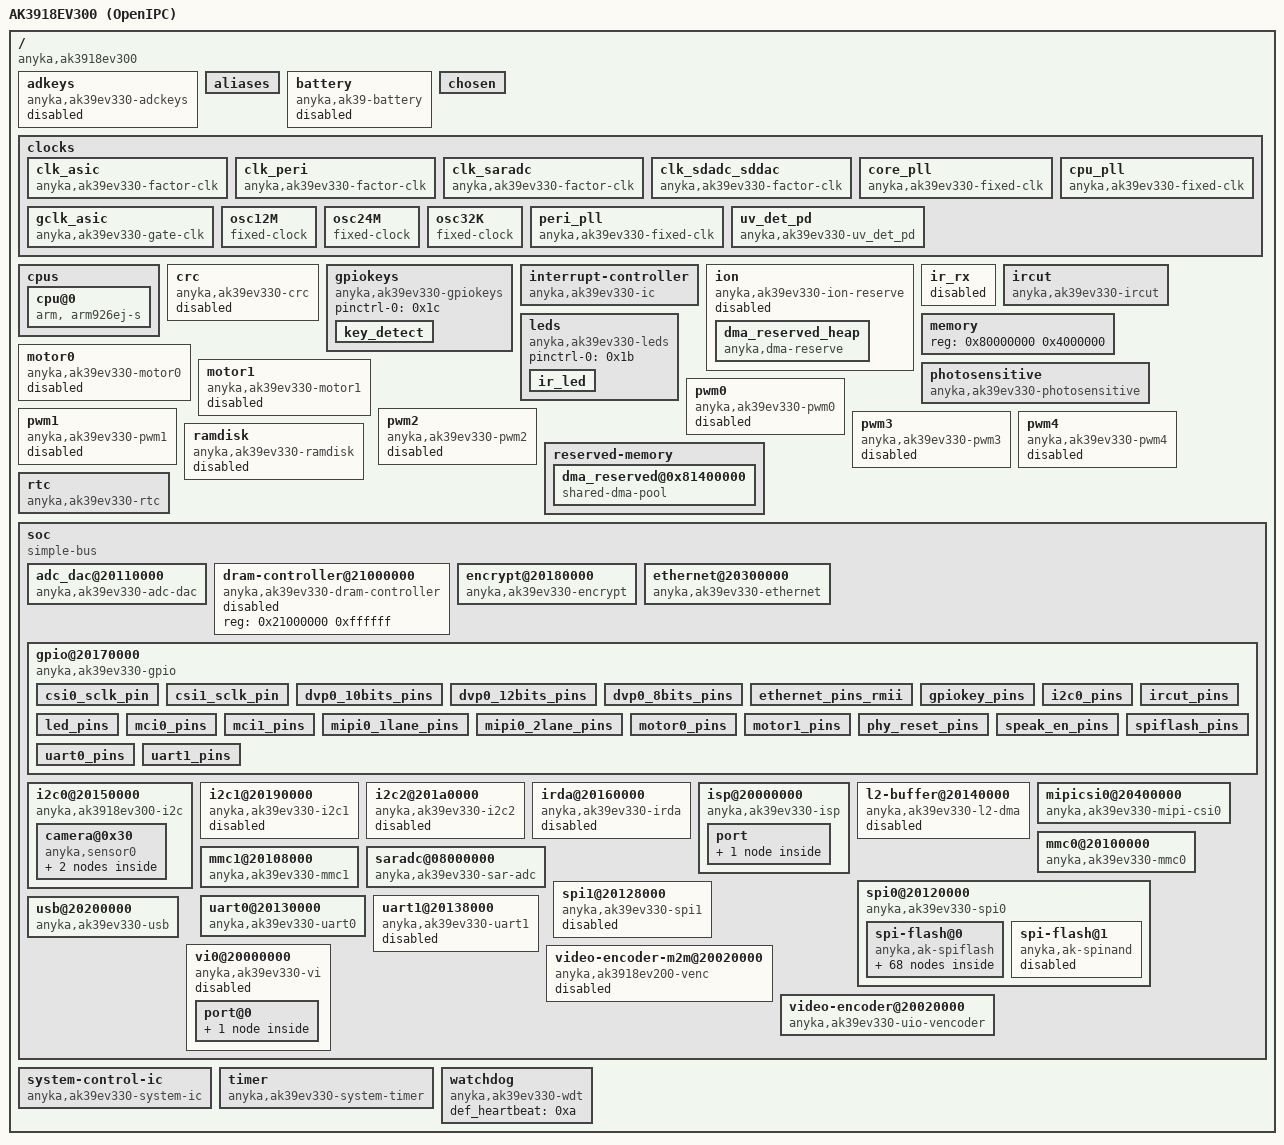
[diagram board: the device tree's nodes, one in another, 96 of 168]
/dts-v1/;

/ {
    #address-cells = <0x1>;
    #size-cells = <0x1>;
    compatible = "anyka,ak3918ev300";
    interrupt-parent = <0x1>;
    model = "AK3918EV300 (OpenIPC)";
    version = "V1.0.00";
    adkeys {
        compatible = "anyka,ak39ev330-adckeys";
        status = "disable";
    };
    aliases {
        adkeys = "/adkeys";
        ethernet0 = "/soc/ethernet@20300000";
        gpio = "/soc/gpio@20170000";
        gpiokeys = "/gpiokeys";
        i2c0 = "/soc/i2c0@20150000";
        i2c1 = "/soc/i2c1@20190000";
        i2c2 = "/soc/i2c2@201a0000";
        intc = "/interrupt-controller";
        ir_rx = "/ir_rx";
        leds = "/leds";
        mipicsi0 = "/soc/mipicsi0@20400000";
        mmc0 = "/soc/mmc0@20100000";
        mmc1 = "/soc/mmc1@20108000";
        motor0 = "/motor0";
        motor1 = "/motor1";
        pwm0 = "/pwm0";
        pwm1 = "/pwm1";
        pwm2 = "/pwm2";
        pwm3 = "/pwm3";
        pwm4 = "/pwm4";
        rtc = "/rtc";
        spi0 = "/soc/spi0@20120000";
        spi1 = "/soc/spi1@20128000";
        uart0 = "/soc/uart0@20130000";
        uart1 = "/soc/uart1@20138000";
        usb = "/soc/usb@20200000";
        watchdog = "/watchdog";
    };
    battery {
        compatible = "anyka,ak39-battery";
        status = "disable";
    };
    chosen {
        bootargs = "console=ttySAK0,115200n8 mem=64M root=/dev/ram0 rdinit=/init initrd=0x80900000,3491008 mtdparts=spi0.0:8192k(all)ro initcall_blacklist=gpio_keys_init panic=0 loglevel=7";
    };
    clocks {
        clk_asic {
            #clock-cells = <0x1>;
            clock-id = <0x0 0x1>;
            clock-output-names = "adchs", "dachs";
            clocks = <0x20>;
            compatible = "anyka,ak39ev330-factor-clk";
            linux,phandle = <0xb>;
            phandle = <0xb>;
        };
        clk_peri {
            #clock-cells = <0x1>;
            clock-id = <0x2 0x3 0x4 0x5 0x6>;
            clock-output-names = "csi_sclk", "csi_pclk", "dsi_pclk", "opclk", "usb_phy";
            clocks = <0x21>;
            compatible = "anyka,ak39ev330-factor-clk";
            linux,phandle = <0x14>;
            phandle = <0x14>;
        };
        clk_saradc {
            #clock-cells = <0x1>;
            clock-id = <0x9>;
            clock-output-names = "saradc";
            clocks = <0x22>;
            compatible = "anyka,ak39ev330-factor-clk";
            linux,phandle = <0xe>;
            phandle = <0xe>;
        };
        clk_sdadc_sddac {
            #clock-cells = <0x1>;
            clock-id = <0x7 0x8>;
            clock-output-names = "clk_sdadc", "clk_sddac";
            clocks = <0x20>;
            compatible = "anyka,ak39ev330-factor-clk";
            linux,phandle = <0xa>;
            phandle = <0xa>;
        };
        core_pll {
            #clock-cells = <0x0>;
            clock-div-n = <0x3>;
            clock-div-od = <0x0>;
            clock-frequency = <0x2625a000>;
            clock-id = <0x3>;
            clock-output-names = "core_pll";
            clocks = <0x1f>;
            compatible = "anyka,ak39ev330-fixed-clk";
            linux,phandle = <0x20>;
            phandle = <0x20>;
        };
        cpu_pll {
            #clock-cells = <0x1>;
            clock-id = <0x0 0x1 0x2>;
            clock-output-names = "jclk", "hclk", "dphy";
            clocks = <0x1f>;
            compatible = "anyka,ak39ev330-fixed-clk";
        };
        gclk_asic {
            #clock-cells = <0x1>;
            clock-ctrlbit = [00 00 00 01 00 00 00 02 00 00 00 03 00 00 00 04 00 00 00 05 00 00 00 06 00 00 00 07 00 00 00 08 00 00 00 09 00 00 00 0a 00 00 00 0b 00 00 00 0c 00 00 00 0d 00 00 00 0e 00 00 00 0f 00 00 00 10 00 00 00 11 00 00 00 13 00 00 00 14 00 00 00 1f 00 00 00 12];
            clock-output-names = "mmc0", "mmc1", "adc", "dac", "spi0", "spi1", "uart0", "uart1", "l2buffer", "i2c0", "irda", "gpio", "ethernet", "encrypt", "usb-otg", "mipi", "i2c1", "isp", "vencoder", "i2c2", "sensor-sclk";
            clocks = <0x20>;
            compatible = "anyka,ak39ev330-gate-clk";
            linux,phandle = <0x5>;
            phandle = <0x5>;
        };
        osc12M {
            #clock-cells = <0x0>;
            clock-frequency = <0xb71b00>;
            clock-output-names = "osc12M";
            clocks = <0x1f>;
            compatible = "fixed-clock";
            linux,phandle = <0x22>;
            phandle = <0x22>;
        };
        osc24M {
            #clock-cells = <0x0>;
            clock-frequency = <0x16e3600>;
            clock-output-names = "osc24M";
            compatible = "fixed-clock";
            linux,phandle = <0x1f>;
            phandle = <0x1f>;
        };
        osc32K {
            #clock-cells = <0x0>;
            clock-frequency = <0x8000>;
            clock-output-names = "osc32K";
            compatible = "fixed-clock";
        };
        peri_pll {
            #clock-cells = <0x0>;
            clock-div-n = <0x2>;
            clock-div-od = <0x1>;
            clock-frequency = <0x23c34600>;
            clock-id = <0x4>;
            clock-output-names = "peri_pll";
            clocks = <0x1f>;
            compatible = "anyka,ak39ev330-fixed-clk";
            linux,phandle = <0x21>;
            phandle = <0x21>;
        };
        uv_det_pd {
            compatible = "anyka,ak39ev330-uv_det_pd";
            enable = <0x1>;
            status = "okay";
            threshold = <0x2>;
        };
    };
    cpus {
        #address-cells = <0x1>;
        #size-cells = <0x0>;
        cpu@0 {
            bus-frequency = <0x0>;
            clock-frequency = <0x0>;
            compatible = "arm, arm926ej-s";
            d-cache-line-size = <0x20>;
            d-cache-size = <0x8000>;
            device_type = "cpu";
            i-cache-line-size = <0x20>;
            i-cache-size = <0x8000>;
            reg = <0x0>;
            timebase-frequency = <0x0>;
        };
    };
    crc {
        compatible = "anyka,ak39ev330-crc";
        status = "disable";
    };
    gpiokeys {
        #address-cells = <0x1>;
        #size-cells = <0x0>;
        compatible = "anyka,ak39ev330-gpiokeys";
        pinctrl-0 = <0x1c>;
        pinctrl-names = "default";
        status = "okay";
        key_detect {
            debounce-interval = <0x64>;
            gpios = <0xd 0x54 0x1>;
            label = "key_detect";
            linux,code = <0x74>;
            wakeup-source;
        };
    };
    interrupt-controller {
        #interrupt-cells = <0x2>;
        bank_irqs = <0x17 0x10>;
        compatible = "anyka,ak39ev330-ic";
        interrupt-controller;
        linux,phandle = <0x1>;
        phandle = <0x1>;
    };
    ion {
        #address-cells = <0x1>;
        #size-cells = <0x1>;
        compatible = "anyka,ak39ev330-ion-reserve";
        heaps-nr = <0x1>;
        memory-region = <0x6>;
        ranges;
        status = "disabled";
        dma_reserved_heap {
            align = <0x4>;
            base-address = <0x81400000>;
            compatible = "anyka,dma-reserve";
            ion-id = <0x1>;
            ion-type = <0x1>;
            size = <0x2000000>;
            status = "okay";
        };
    };
    ir_rx {
        status = "disable";
    };
    ircut {
        compatible = "anyka,ak39ev330-ircut";
        ircut-a = "0";
        ircut-a-day-level = "0";
        pinctrl-0 = <0x1a>;
        pinctrl-names = "default";
        status = "okay";
    };
    leds {
        compatible = "anyka,ak39ev330-leds";
        pinctrl-0 = <0x1b>;
        pinctrl-names = "default";
        status = "okay";
        ir_led {
            gpios = <0xd 0x5 0x0>;
            label = "irled";
        };
    };
    memory {
        device_type = "memory";
        reg = <0x80000000 0x4000000>;
    };
    motor0 {
        attach-timer = <0x2>;
        boundary-steps = <0x32>;
        compatible = "anyka,ak39ev330-motor0";
        part-number = "HZF-24BYJ48";
        pinctrl-0 = <0x1d>;
        pinctrl-names = "default";
        pwm-pins = <0x44 0x9 0x8 0x7>;
        pwm-tbl-cw = <0x9 0x1 0x3 0x2 0x6 0x4 0xc 0x8>;
        speed-step = <0xc8>;
        status = "disable";
        steps-one-circle = <0x1000>;
        total-steps = <0x9c4>;
    };
    motor1 {
        attach-timer = <0x3>;
        boundary-steps = <0x32>;
        compatible = "anyka,ak39ev330-motor1";
        part-number = "HZF-24BYJ48";
        pinctrl-0 = <0x1e>;
        pinctrl-names = "default";
        pwm-pins = <0x6 0x43 0x42 0x41>;
        pwm-tbl-cw = <0x9 0x1 0x3 0x2 0x6 0x4 0xc 0x8>;
        speed-step = <0xc8>;
        status = "disable";
        steps-one-circle = <0x1000>;
        total-steps = <0x258>;
    };
    photosensitive {
        compatible = "anyka,ak39ev330-photosensitive";
        photosensitive-day-level = "high";
        photosensitive-higher-level = "900";
        photosensitive-lower-level = "400";
        photosensitive-port = "saradc0";
        status = "okay";
    };
    pwm0 {
        compatible = "anyka,ak39ev330-pwm0";
        duty-ns = <0x7a120>;
        period-ns = <0xf4240>;
        pinctrl-names = "default";
        pwm-enable = <0x1>;
        status = "disable";
    };
    pwm1 {
        compatible = "anyka,ak39ev330-pwm1";
        duty-ns = <0x7a120>;
        period-ns = <0xf4240>;
        pinctrl-names = "default";
        pwm-enable = <0x1>;
        status = "disable";
    };
    pwm2 {
        compatible = "anyka,ak39ev330-pwm2";
        duty-ns = <0x7a120>;
        period-ns = <0xf4240>;
        pinctrl-names = "default";
        pwm-enable = <0x1>;
        status = "disable";
    };
    pwm3 {
        compatible = "anyka,ak39ev330-pwm3";
        duty-ns = <0x7a120>;
        period-ns = <0xf4240>;
        pinctrl-names = "default";
        pwm-enable = <0x1>;
        status = "disable";
    };
    pwm4 {
        compatible = "anyka,ak39ev330-pwm4";
        duty-ns = <0x7a120>;
        period-ns = <0xf4240>;
        pinctrl-names = "default";
        pwm-enable = <0x1>;
        status = "disable";
    };
    ramdisk {
        compatible = "anyka,ak39ev330-ramdisk";
        status = "disabled";
    };
    reserved-memory {
        #address-cells = <0x1>;
        #size-cells = <0x1>;
        ranges;
        dma_reserved@0x81400000 {
            compatible = "shared-dma-pool";
            linux,phandle = <0x6>;
            no-map;
            phandle = <0x6>;
            reg = <0x81400000 0x1800000>;
            size = <0x1800000>;
            status = "okay";
        };
    };
    rtc {
        adjust-time = <0x1d4c0>;
        compatible = "anyka,ak39ev330-rtc";
        osc-select = <0x1>;
        status = "okay";
    };
    soc {
        #address-cells = <0x1>;
        #size-cells = <0x1>;
        compatible = "simple-bus";
        ranges;
        adc_dac@20110000 {
            clock-names = "sdadc_gclk", "sdadc_clk", "sdadchs_clk", "sddac_gclk", "sddac_clk", "sddachs_clk";
            clocks = <0x5 0x2 0xa 0x0 0xb 0x0 0x5 0x3 0xa 0x1 0xb 0x1>;
            compatible = "anyka,ak39ev330-adc-dac";
            interrupts = <0x6 0x0 0x7 0x0>;
            pinctrl-0 = <0xc>;
            pinctrl-names = "default";
            reg = <0x8000000 0xffff 0x20110000 0x7fff>;
            speak-gpios = <0xd 0x4f 0x1>;
            speak-gpios-en = <0x1>;
            status = "okay";
        };
        dram-controller@21000000 {
            compatible = "anyka,ak39ev330-dram-controller";
            reg = <0x21000000 0xffffff>;
            status = "disable";
        };
        encrypt@20180000 {
            clocks = <0x5 0xd>;
            compatible = "anyka,ak39ev330-encrypt";
            encrypt-mode = <0x1>;
            interrupts = <0x11 0x0>;
            reg = <0x20180000 0xffff>;
            status = "okay";
        };
        ethernet@20300000 {
            clock-names = "ethernet", "opclk";
            clocks = <0x5 0xc 0x14 0x3>;
            compatible = "anyka,ak39ev330-ethernet";
            interrupts = <0x10 0x0>;
            mac-address = [00 00 00 00 00 00];
            phy-address = <0x1>;
            pinctrl-0 = <0x15>;
            pinctrl-names = "default";
            reg = <0x20300000 0x1fff>;
            status = "okay";
        };
        gpio@20170000 {
            #gpio-cells = <0x2>;
            #interrupt-cells = <0x2>;
            clocks = <0x5 0xb>;
            compatible = "anyka,ak39ev330-gpio";
            gpio-controller;
            interrupt-controller;
            interrupts = <0xf 0x0>;
            linux,phandle = <0xd>;
            phandle = <0xd>;
            reg = <0x20170000 0xffff 0x20400000 0x1000 0x20480000 0x1000>;
            status = "okay";
            csi0_sclk_pin {
                anyka,function = <0x0>;
                anyka,pins = <0x40>;
                anyka,pull = <0x1>;
                linux,phandle = <0x18>;
                phandle = <0x18>;
            };
            csi1_sclk_pin {
                anyka,function = <0x2>;
                anyka,pins = <0x3>;
                anyka,pull = <0x1>;
                linux,phandle = <0x19>;
                phandle = <0x19>;
            };
            dvp0_10bits_pins {
                anyka,function = <0x0>;
                anyka,map = <0x49 0x4b 0x48 0x4a 0x46 0x47 0x47 0x46 0x4a 0x48 0x4b 0x49>;
                anyka,pins = <0x8 0x9 0x40 0x41 0x42 0x43 0x44 0x45 0x46 0x47 0x48 0x49 0x4a 0x4b>;
                anyka,pull = <0x1>;
                linux,phandle = <0x2>;
                phandle = <0x2>;
            };
            dvp0_12bits_pins {
                anyka,function = <0x0>;
                anyka,map = <0x49 0x4b 0x48 0x4a 0x46 0x47 0x47 0x46 0x4a 0x48 0x4b 0x49>;
                anyka,pins = <0x6 0x7 0x8 0x9 0x40 0x41 0x42 0x43 0x44 0x45 0x46 0x47 0x48 0x49 0x4a 0x4b>;
                anyka,pull = <0x1>;
                linux,phandle = <0x16>;
                phandle = <0x16>;
            };
            dvp0_8bits_pins {
                anyka,function = <0x0>;
                anyka,map = <0x49 0x4b 0x48 0x4a 0x46 0x47 0x47 0x46 0x4a 0x48 0x4b 0x49>;
                anyka,pins = <0x40 0x41 0x42 0x43 0x44 0x45 0x46 0x47 0x48 0x49 0x4a 0x4b>;
                anyka,pull = <0x1>;
                linux,phandle = <0x17>;
                phandle = <0x17>;
            };
            ethernet_pins_rmii {
                anyka,function = <0x1>;
                anyka,pins = <0xa 0xb 0xd 0xe 0xf 0x13 0x14 0x17 0x18 0x2f>;
                anyka,pull = <0x11 0x10 0x11 0x11 0x11 0x11 0x11 0x11 0x11 0x1>;
                linux,phandle = <0x15>;
                phandle = <0x15>;
            };
            gpiokey_pins {
                anyka,function = <0x0>;
                anyka,pins = <0x54>;
                anyka,pull = <0x10>;
                linux,phandle = <0x1c>;
                phandle = <0x1c>;
            };
            i2c0_pins {
                anyka,function = <0x1>;
                anyka,pins = <0x1b 0x1c>;
                anyka,pull = <0x10>;
                linux,phandle = <0x12>;
                phandle = <0x12>;
            };
            ircut_pins {
                anyka,function = <0x0>;
                anyka,pins = <0x0>;
                anyka,pull = <0x10>;
                linux,phandle = <0x1a>;
                phandle = <0x1a>;
            };
            led_pins {
                anyka,function = <0x0>;
                anyka,pins = <0x5>;
                anyka,pull = <0x10>;
                linux,phandle = <0x1b>;
                phandle = <0x1b>;
            };
            mci0_pins {
                anyka,function = <0x1 0x1 0x1 0x1 0x2 0x2>;
                anyka,pins = <0x1f 0x20 0x21 0x22 0x50 0x51>;
                anyka,pull = <0x10>;
                linux,phandle = <0x8>;
                phandle = <0x8>;
            };
            mci1_pins {
                anyka,function = <0x1 0x1 0x2 0x2 0x2 0x2>;
                anyka,pins = <0x29 0x2a 0x18 0x17 0x14 0x13>;
                anyka,pull = <0x10>;
                linux,phandle = <0x9>;
                phandle = <0x9>;
            };
            mipi0_1lane_pins {
                anyka,function = <0x3 0x3 0x3 0x2 0x2 0x2>;
                anyka,pins = <0x46 0x47 0x48 0x49 0x4a 0x4b>;
                anyka,pull = <0x10>;
                linux,phandle = <0x3>;
                phandle = <0x3>;
            };
            mipi0_2lane_pins {
                anyka,function = <0x3 0x3 0x3 0x2 0x2 0x2>;
                anyka,pins = <0x46 0x47 0x48 0x49 0x4a 0x4b>;
                anyka,pull = <0x10>;
                linux,phandle = <0x4>;
                phandle = <0x4>;
            };
            motor0_pins {
                anyka,function = <0x1>;
                anyka,pins = <0x44 0x9 0x8 0x7>;
                anyka,pull = <0x10>;
                linux,phandle = <0x1d>;
                phandle = <0x1d>;
            };
            motor1_pins {
                anyka,function = <0x1>;
                anyka,pins = <0x6 0x43 0x42 0x41>;
                anyka,pull = <0x10>;
                linux,phandle = <0x1e>;
                phandle = <0x1e>;
            };
            phy_reset_pins {
                anyka,function = <0x0>;
                anyka,pins = <0x52>;
                anyka,pull = <0x10>;
            };
            speak_en_pins {
                anyka,function = <0x0>;
                anyka,pins = <0x4f>;
                anyka,pull = <0x10>;
                linux,phandle = <0xc>;
                phandle = <0xc>;
            };
            spiflash_pins {
                anyka,function = <0x1 0x1 0x2 0x2>;
                anyka,pins = <0x19 0x1a 0x23 0x24>;
                anyka,pull = <0x10>;
                linux,phandle = <0xf>;
                phandle = <0xf>;
            };
            uart0_pins {
                anyka,function = <0x1>;
                anyka,pins = <0x1 0x2>;
                anyka,pull = <0x10>;
                linux,phandle = <0x10>;
                phandle = <0x10>;
            };
            uart1_pins {
                anyka,function = <0x2>;
                anyka,pins = <0x0 0x5>;
                anyka,pull = <0x10>;
                linux,phandle = <0x11>;
                phandle = <0x11>;
            };
        };
        i2c0@20150000 {
            #address-cells = <0x1>;
            #size-cells = <0x0>;
            clock-frequency = <0x4c2c0>;
            clocks = <0x5 0x9>;
            compatible = "anyka,ak3918ev300-i2c";
            interrupts = <0xd 0x0>;
            pinctrl-0 = <0x12>;
            pinctrl-names = "default";
            reg = <0x20150000 0xffff>;
            sda-delay = <0x64>;
            status = "okay";
            camera@0x30 {
                compatible = "anyka,sensor0";
                pwdn-gpio = <0xd 0xffff 0x1>;
                reg = <0x30>;
                reset-gpio = <0xd 0x31 0x1>;
                port {
                    endpoint@0 {
                        linux,phandle = <0x7>;
                        phandle = <0x7>;
                        remote-endpoint = <0x13>;
                    };
                };
            };
        };
        i2c1@20190000 {
            clock-frequency = <0x4c2c0>;
            clocks = <0x5 0x10>;
            compatible = "anyka,ak39ev330-i2c1";
            interrupts = <0x14 0x0>;
            pinctrl-names = "default";
            reg = <0x20190000 0xffff>;
            sda-delay = <0x64>;
            status = "disabled";
        };
        i2c2@201a0000 {
            #address-cells = <0x1>;
            #size-cells = <0x0>;
            clock-frequency = <0x4c2c0>;
            clocks = <0x5 0x13>;
            compatible = "anyka,ak39ev330-i2c2";
            interrupts = <0x1d 0x0>;
            pinctrl-names = "default";
            reg = <0x201a0000 0xffff>;
            sda-delay = <0x64>;
            status = "disabled";
        };
        irda@20160000 {
            compatible = "anyka,ak39ev330-irda";
            interrupts = <0xe 0x0>;
            reg = <0x20160000 0xffff>;
            status = "disable";
        };
        isp@20000000 {
            clock-names = "camera";
            clocks = <0x5 0x11>;
            compatible = "anyka,ak39ev330-isp";
            interrupts = <0x1 0x0>;
            mclk-mhz = <0x18>;
            memory-region = <0x6>;
            pinctrl-0 = <0x2>;
            pinctrl-1 = <0x3>;
            pinctrl-2 = <0x4>;
            pinctrl-names = "default", "mipi0_1lane", "mipi0_2lane";
            reg = <0x20000000 0xffff>;
            status = "okay";
            port {
                endpoint {
                    linux,phandle = <0x13>;
                    phandle = <0x13>;
                    remote-endpoint = <0x7>;
                };
            };
        };
        l2-buffer@20140000 {
            clocks = <0x5 0x8>;
            compatible = "anyka,ak39ev330-l2-dma";
            interrupts = <0xc 0x0>;
            reg = <0x20140000 0xffff>;
            status = "disable";
        };
        mipicsi0@20400000 {
            clock-names = "mipi_csi_clk";
            clocks = <0x5 0xf>;
            compatible = "anyka,ak39ev330-mipi-csi0";
            reg = <0x20400000 0x7ffff>;
            status = "okay";
        };
        mmc0@20100000 {
            bus-width = <0x4>;
            cap-sd-highspeed;
            cd_clk;
            clocks = <0x5 0x0>;
            compatible = "anyka,ak39ev330-mmc0";
            interrupts = <0x4 0x0 0x16 0x0>;
            max-frequency = <0x2faf080>;
            pinctrl-0 = <0x8>;
            pinctrl-names = "default";
            reg = <0x20100000 0x7fff>;
            status = "okay";
        };
        mmc1@20108000 {
            bus-width = <0x4>;
            cap-sd-highspeed;
            cap-sdio-irq;
            clocks = <0x5 0x1>;
            compatible = "anyka,ak39ev330-mmc1";
            interrupts = <0x5 0x0 0x16 0x0>;
            max-frequency = <0x2faf080>;
            non-removable;
            pinctrl-0 = <0x9>;
            pinctrl-names = "default";
            reg = <0x20108000 0x7fff>;
            status = "okay";
        };
        saradc@08000000 {
            battery-divider = <0x1>;
            clocks = <0xe 0x0>;
            compatible = "anyka,ak39ev330-sar-adc";
            interrupts = <0x1 0x1>;
            reg = <0x8000000 0x100>;
            sampling-num = <0x3>;
            status = "okay";
            vref-select = <0x1>;
        };
        spi0@20120000 {
            #address-cells = <0x1>;
            #size-cells = <0x0>;
            clock-names = "spi0";
            clocks = <0x5 0x4>;
            compatible = "anyka,ak39ev330-spi0";
            interrupts = <0x8 0x0>;
            pinctrl-0 = <0xf>;
            pinctrl-names = "default";
            reg = <0x20120000 0x7fff>;
            status = "okay";
            spi-flash@0 {
                #address-cells = <0x1>;
                #size-cells = <0x0>;
                bus-width = <0x1>;
                compatible = "anyka,ak-spiflash";
                reg = <0x0>;
                spi-max-frequency = <0x1c9c380>;
                status = "okay";
                spi-norflash@0 {
                    compatible = "atmel,at25fs010";
                    norflash-b-bp0 = <0x2>;
                    norflash-b-bp1 = <0x3>;
                    norflash-b-bp3 = <0x5>;
                    norflash-b-bp4 = <0x6>;
                    norflash-b-cmp = <0x7>;
                    norflash-b-wel = <0x1>;
                    norflash-b-wip = <0x0>;
                    norflash-ext-id = <0x0>;
                    norflash-flags = <0x1000>;
                    norflash-jedec-id = <0x1f6601>;
                    norflash-n-sectors = <0x4>;
                    norflash-name = "at25fs010";
                    norflash-sector-size = <0x8000>;
                    norflash-wr_flags = <0x1>;
                    rd_status_cmd = <0x5>;
                    reg = <0x0>;
                    status = "disable";
                    wr_mode = <0x0>;
                    wr_status_cmd = <0x1>;
                };
                spi-norflash@1 {
                    compatible = "atmel,at25fs040";
                    norflash-b-bp0 = <0x2>;
                    norflash-b-bp1 = <0x3>;
                    norflash-b-bp2 = <0x4>;
                    norflash-b-bp3 = <0x5>;
                    norflash-b-bp4 = <0x6>;
                    norflash-b-cmp = <0x7>;
                    norflash-b-wel = <0x1>;
                    norflash-b-wip = <0x0>;
                    norflash-ext-id = <0x0>;
                    norflash-flags = <0x1000>;
                    norflash-jedec-id = <0x1f6604>;
                    norflash-n-sectors = <0x8>;
                    norflash-name = "at25fs040";
                    norflash-sector-size = <0x10000>;
                    norflash-wr_flags = <0x1>;
                    rd_status_cmd = <0x5>;
                    reg = <0x1>;
                    status = "disable";
                    wr_mode = <0x0>;
                    wr_status_cmd = <0x1>;
                };
                spi-norflash@10 {
                    compatible = "macronix,mx25l12805d";
                    norflash-b-bp0 = <0x2>;
                    norflash-b-bp1 = <0x3>;
                    norflash-b-bp2 = <0x4>;
                    norflash-b-bp3 = <0x5>;
                    norflash-b-wel = <0x1>;
                    norflash-b-wip = <0x0>;
                    norflash-ext-id = <0x0>;
                    norflash-flags = <0x1450>;
                    norflash-jedec-id = <0xc22018>;
                    norflash-n-sectors = <0x100>;
                    norflash-name = "mx25l12805d";
                    norflash-sector-size = <0x10000>;
                    norflash-wr_flags = <0x1>;
                    rd_status_cmd = <0x5>;
                    reg = <0xa>;
                    status = "disable";
                    wr_mode = <0x0>;
                    wr_status_cmd = <0x1>;
                };
                spi-norflash@11 {
                    compatible = "macronix,mx25l12855e";
                    norflash-b-bp0 = <0x2>;
                    norflash-b-bp1 = <0x3>;
                    norflash-b-bp2 = <0x4>;
                    norflash-b-bp3 = <0x5>;
                    norflash-b-qe = <0x6>;
                    norflash-b-wel = <0x1>;
                    norflash-b-wip = <0x0>;
                    norflash-ext-id = <0x0>;
                    norflash-flags = <0x1020>;
                    norflash-jedec-id = <0xc22018>;
                    norflash-n-sectors = <0x100>;
                    norflash-name = "mx25l12855e";
                    norflash-sector-size = <0x10000>;
                    norflash-wr_flags = <0x1>;
                    rd_status_cmd = <0x5>;
                    reg = <0xb>;
                    status = "disable";
                    wr_mode = <0x0>;
                    wr_status_cmd = <0x1>;
                };
                spi-norflash@12 {
                    compatible = "spansion,s25fl129p0";
                    norflash-b-bp0 = <0x2>;
                    norflash-b-bp1 = <0x3>;
                    norflash-b-bp2 = <0x4>;
                    norflash-b-wel = <0x1>;
                    norflash-b-wip = <0x0>;
                    norflash-ext-id = <0x4d00>;
                    norflash-flags = <0x0>;
                    norflash-jedec-id = <0x12018>;
                    norflash-n-sectors = <0x40>;
                    norflash-name = "s25fl129p0";
                    norflash-sector-size = <0x40000>;
                    norflash-wr_flags = <0x1>;
                    rd_status_cmd = <0x5>;
                    reg = <0xc>;
                    status = "disable";
                    wr_mode = <0x0>;
                    wr_status_cmd = <0x1>;
                };
                spi-norflash@13 {
                    compatible = "spansion,s25fl129p1";
                    norflash-b-bp0 = <0x2>;
                    norflash-b-bp1 = <0x3>;
                    norflash-b-bp2 = <0x4>;
                    norflash-b-wel = <0x1>;
                    norflash-b-wip = <0x0>;
                    norflash-ext-id = <0x4d01>;
                    norflash-flags = <0x0>;
                    norflash-jedec-id = <0x12018>;
                    norflash-n-sectors = <0x100>;
                    norflash-name = "s25fl129p1";
                    norflash-sector-size = <0x10000>;
                    norflash-wr_flags = <0x1>;
                    rd_status_cmd = <0x5>;
                    reg = <0xd>;
                    status = "disable";
                    wr_mode = <0x0>;
                    wr_status_cmd = <0x1>;
                };
                spi-norflash@14 {
                    compatible = "sst,sst25vf040b";
                    norflash-b-bp0 = <0x2>;
                    norflash-b-bp1 = <0x3>;
                    norflash-b-bp2 = <0x4>;
                    norflash-b-bp3 = <0x5>;
                    norflash-b-wel = <0x1>;
                    norflash-b-wip = <0x0>;
                    norflash-ext-id = <0x0>;
                    norflash-flags = <0x1000>;
                    norflash-jedec-id = <0xbf258d>;
                    norflash-n-sectors = <0x8>;
                    norflash-name = "sst25vf040b";
                    norflash-sector-size = <0x10000>;
                    norflash-wr_flags = <0x1>;
                    rd_status_cmd = <0x5>;
                    reg = <0xe>;
                    status = "disable";
                    wr_mode = <0x0>;
                    wr_status_cmd = <0x1>;
                };
                spi-norflash@15 {
                    compatible = "sst,sst25vf080b";
                    norflash-b-bp0 = <0x2>;
                    norflash-b-bp1 = <0x3>;
                    norflash-b-bp2 = <0x4>;
                    norflash-b-bp3 = <0x5>;
                    norflash-b-wel = <0x1>;
                    norflash-b-wip = <0x0>;
                    norflash-ext-id = <0x0>;
                    norflash-flags = <0x1000>;
                    norflash-jedec-id = <0xbf258e>;
                    norflash-n-sectors = <0x10>;
                    norflash-name = "sst25vf080b";
                    norflash-sector-size = <0x10000>;
                    norflash-wr_flags = <0x1>;
                    rd_status_cmd = <0x5>;
                    reg = <0xf>;
                    status = "disable";
                    wr_mode = <0x0>;
                    wr_status_cmd = <0x1>;
                };
                spi-norflash@16 {
                    compatible = "sst,sst25vf016b";
                    norflash-b-bp0 = <0x2>;
                    norflash-b-bp1 = <0x3>;
                    norflash-b-bp2 = <0x4>;
                    norflash-b-bp3 = <0x5>;
                    norflash-b-wel = <0x1>;
                    norflash-b-wip = <0x0>;
                    norflash-ext-id = <0x0>;
                    norflash-flags = <0x1000>;
                    norflash-jedec-id = <0xbf2541>;
                    norflash-n-sectors = <0x20>;
                    norflash-name = "sst25vf016b";
                    norflash-sector-size = <0x10000>;
                    norflash-wr_flags = <0x1>;
                    rd_status_cmd = <0x5>;
                    reg = <0x10>;
                    status = "disable";
                    wr_mode = <0x0>;
                    wr_status_cmd = <0x1>;
                };
                spi-norflash@17 {
                    compatible = "sst,sst25vf032b";
                    norflash-b-bp0 = <0x2>;
                    norflash-b-bp1 = <0x3>;
                    norflash-b-bp2 = <0x4>;
                    norflash-b-bp3 = <0x5>;
                    norflash-b-wel = <0x1>;
                    norflash-b-wip = <0x0>;
                    norflash-ext-id = <0x0>;
                    norflash-flags = <0x1000>;
                    norflash-jedec-id = <0xbf254a>;
                    norflash-n-sectors = <0x40>;
                    norflash-name = "sst25vf032b";
                    norflash-sector-size = <0x10000>;
                    norflash-wr_flags = <0x1>;
                    rd_status_cmd = <0x5>;
                    reg = <0x11>;
                    status = "disable";
                    wr_mode = <0x0>;
                    wr_status_cmd = <0x1>;
                };
                spi-norflash@18 {
                    compatible = "sst,sst25wf512";
                    norflash-b-bp0 = <0x2>;
                    norflash-b-bp1 = <0x3>;
                    norflash-b-bp2 = <0x4>;
                    norflash-b-wel = <0x1>;
                    norflash-b-wip = <0x0>;
                    norflash-ext-id = <0x0>;
                    norflash-flags = <0x1000>;
                    norflash-jedec-id = <0xbf2501>;
                    norflash-n-sectors = <0x1>;
                    norflash-name = "sst25wf512";
                    norflash-sector-size = <0x10000>;
                    norflash-wr_flags = <0x1>;
                    rd_status_cmd = <0x5>;
                    reg = <0x12>;
                    status = "disable";
                    wr_mode = <0x0>;
                    wr_status_cmd = <0x1>;
                };
                spi-norflash@19 {
                    compatible = "sst,sst25wf010";
                    norflash-b-bp0 = <0x2>;
                    norflash-b-bp1 = <0x3>;
                    norflash-b-bp2 = <0x4>;
                    norflash-b-wel = <0x1>;
                    norflash-b-wip = <0x0>;
                    norflash-ext-id = <0x0>;
                    norflash-flags = <0x1000>;
                    norflash-jedec-id = <0xbf2502>;
                    norflash-n-sectors = <0x2>;
                    norflash-name = "sst25wf010";
                    norflash-sector-size = <0x10000>;
                    norflash-wr_flags = <0x1>;
                    rd_status_cmd = <0x5>;
                    reg = <0x13>;
                    status = "disable";
                    wr_mode = <0x0>;
                    wr_status_cmd = <0x1>;
                };
                spi-norflash@2 {
                    compatible = "atmel,at25df041a";
                    norflash-b-wel = <0x1>;
                    norflash-b-wip = <0x0>;
                    norflash-ext-id = <0x0>;
                    norflash-flags = <0x1000>;
                    norflash-jedec-id = <0x1f4401>;
                    norflash-n-sectors = <0x8>;
                    norflash-name = "at25df041a";
                    norflash-sector-size = <0x10000>;
                    norflash-wr_flags = <0x1>;
                    rd_status_cmd = <0x5>;
                    reg = <0x2>;
                    status = "disable";
                    wr_mode = <0x0>;
                    wr_status_cmd = <0x1>;
                };
                spi-norflash@20 {
                    compatible = "sst,sst25wf020";
                    norflash-b-bp0 = <0x2>;
                    norflash-b-bp1 = <0x3>;
                    norflash-b-wel = <0x1>;
                    norflash-b-wip = <0x0>;
                    norflash-ext-id = <0x0>;
                    norflash-flags = <0x1000>;
                    norflash-jedec-id = <0xbf2503>;
                    norflash-n-sectors = <0x4>;
                    norflash-name = "sst25wf020";
                    norflash-sector-size = <0x10000>;
                    norflash-wr_flags = <0x1>;
                    rd_status_cmd = <0x5>;
                    reg = <0x14>;
                    status = "disable";
                    wr_mode = <0x0>;
                    wr_status_cmd = <0x1>;
                };
                spi-norflash@21 {
                    compatible = "sst,sst25wf040";
                    norflash-b-bp0 = <0x2>;
                    norflash-b-bp1 = <0x3>;
                    norflash-b-bp2 = <0x4>;
                    norflash-b-wel = <0x1>;
                    norflash-b-wip = <0x0>;
                    norflash-ext-id = <0x0>;
                    norflash-flags = <0x1000>;
                    norflash-jedec-id = <0xbf2504>;
                    norflash-n-sectors = <0x8>;
                    norflash-name = "sst25wf040";
                    norflash-sector-size = <0x10000>;
                    norflash-wr_flags = <0x1>;
                    rd_status_cmd = <0x5>;
                    reg = <0x15>;
                    status = "disable";
                    wr_mode = <0x0>;
                    wr_status_cmd = <0x1>;
                };
                spi-norflash@22 {
                    compatible = "st,m25p05";
                    norflash-b-bp0 = <0x2>;
                    norflash-b-bp1 = <0x3>;
                    norflash-b-wel = <0x1>;
                    norflash-b-wip = <0x0>;
                    norflash-ext-id = <0x0>;
                    norflash-flags = <0x0>;
                    norflash-jedec-id = <0x202010>;
                    norflash-n-sectors = <0x2>;
                    norflash-name = "m25p05";
                    norflash-sector-size = <0x8000>;
                    norflash-wr_flags = <0x1>;
                    rd_status_cmd = <0x5>;
                    reg = <0x16>;
                    status = "disable";
                    wr_mode = <0x0>;
                    wr_status_cmd = <0x1>;
                };
                spi-norflash@23 {
                    compatible = "st,m25p10";
                    norflash-b-bp0 = <0x2>;
                    norflash-b-bp1 = <0x3>;
                    norflash-b-wel = <0x1>;
                    norflash-b-wip = <0x0>;
                    norflash-ext-id = <0x0>;
                    norflash-flags = <0x0>;
                    norflash-jedec-id = <0x202011>;
                    norflash-n-sectors = <0x4>;
                    norflash-name = "m25p10";
                    norflash-sector-size = <0x8000>;
                    norflash-wr_flags = <0x1>;
                    rd_status_cmd = <0x5>;
                    reg = <0x17>;
                    status = "disable";
                    wr_mode = <0x0>;
                    wr_status_cmd = <0x1>;
                };
                spi-norflash@24 {
                    compatible = "st,m25p20";
                    norflash-b-bp0 = <0x2>;
                    norflash-b-bp1 = <0x3>;
                    norflash-b-bp2 = <0x4>;
                    norflash-b-wel = <0x1>;
                    norflash-b-wip = <0x0>;
                    norflash-ext-id = <0x0>;
                    norflash-flags = <0x0>;
                    norflash-jedec-id = <0x202012>;
                    norflash-n-sectors = <0x4>;
                    norflash-name = "m25p20";
                    norflash-sector-size = <0x10000>;
                    norflash-wr_flags = <0x1>;
                    rd_status_cmd = <0x5>;
                    reg = <0x18>;
                    status = "disable";
                    wr_mode = <0x0>;
                    wr_status_cmd = <0x1>;
                };
                spi-norflash@25 {
                    compatible = "st,m25p40";
                    norflash-b-bp0 = <0x2>;
                    norflash-b-bp1 = <0x3>;
                    norflash-b-bp2 = <0x4>;
                    norflash-b-wel = <0x1>;
                    norflash-b-wip = <0x0>;
                    norflash-ext-id = <0x0>;
                    norflash-flags = <0x0>;
                    norflash-jedec-id = <0x202013>;
                    norflash-n-sectors = <0x8>;
                    norflash-name = "m25p40";
                    norflash-sector-size = <0x10000>;
                    norflash-wr_flags = <0x1>;
                    rd_status_cmd = <0x5>;
                    reg = <0x19>;
                    status = "disable";
                    wr_mode = <0x0>;
                    wr_status_cmd = <0x1>;
                };
                spi-norflash@26 {
                    compatible = "st,m25p80";
                    norflash-b-bp0 = <0x2>;
                    norflash-b-bp1 = <0x3>;
                    norflash-b-bp2 = <0x4>;
                    norflash-b-wel = <0x1>;
                    norflash-b-wip = <0x0>;
                    norflash-ext-id = <0x0>;
                    norflash-flags = <0x0>;
                    norflash-jedec-id = <0x202014>;
                    norflash-n-sectors = <0x10>;
                    norflash-name = "m25p80";
                    norflash-sector-size = <0x10000>;
                    norflash-wr_flags = <0x1>;
                    rd_status_cmd = <0x5>;
                    reg = <0x1a>;
                    status = "disable";
                    wr_mode = <0x0>;
                    wr_status_cmd = <0x1>;
                };
                spi-norflash@27 {
                    compatible = "st,m25p16";
                    norflash-b-bp0 = <0x2>;
                    norflash-b-bp1 = <0x3>;
                    norflash-b-bp2 = <0x4>;
                    norflash-b-wel = <0x1>;
                    norflash-b-wip = <0x0>;
                    norflash-ext-id = <0x0>;
                    norflash-flags = <0x0>;
                    norflash-jedec-id = <0x202015>;
                    norflash-n-sectors = <0x20>;
                    norflash-name = "m25p16";
                    norflash-sector-size = <0x10000>;
                    norflash-wr_flags = <0x1>;
                    rd_status_cmd = <0x5>;
                    reg = <0x1b>;
                    status = "disable";
                    wr_mode = <0x0>;
                    wr_status_cmd = <0x1>;
                };
                spi-norflash@28 {
                    compatible = "st,m25p32";
                    norflash-b-bp0 = <0x2>;
                    norflash-b-bp1 = <0x3>;
                    norflash-b-bp2 = <0x4>;
                    norflash-b-wel = <0x1>;
                    norflash-b-wip = <0x0>;
                    norflash-ext-id = <0x0>;
                    norflash-flags = <0x0>;
                    norflash-jedec-id = <0x202016>;
                    norflash-n-sectors = <0x40>;
                    norflash-name = "m25p32";
                    norflash-sector-size = <0x10000>;
                    norflash-wr_flags = <0x1>;
                    rd_status_cmd = <0x5>;
                    reg = <0x1c>;
                    status = "disable";
                    wr_mode = <0x0>;
                    wr_status_cmd = <0x1>;
                };
                spi-norflash@29 {
                    compatible = "st,m25p64";
                    norflash-b-bp0 = <0x2>;
                    norflash-b-bp1 = <0x3>;
                    norflash-b-bp2 = <0x4>;
                    norflash-b-wel = <0x1>;
                    norflash-b-wip = <0x0>;
                    norflash-ext-id = <0x0>;
                    norflash-flags = <0x0>;
                    norflash-jedec-id = <0x202017>;
                    norflash-n-sectors = <0x80>;
                    norflash-name = "m25p64";
                    norflash-sector-size = <0x10000>;
                    norflash-wr_flags = <0x1>;
                    rd_status_cmd = <0x5>;
                    reg = <0x1d>;
                    status = "disable";
                    wr_mode = <0x0>;
                    wr_status_cmd = <0x1>;
                };
                spi-norflash@3 {
                    compatible = "atmel,at25df641";
                    norflash-b-wel = <0x1>;
                    norflash-b-wip = <0x0>;
                    norflash-ext-id = <0x0>;
                    norflash-flags = <0x1000>;
                    norflash-jedec-id = <0x1f4800>;
                    norflash-n-sectors = <0x80>;
                    norflash-name = "at25df641";
                    norflash-sector-size = <0x10000>;
                    norflash-wr_flags = <0x2>;
                    rd_status_cmd = <0x5>;
                    reg = <0x3>;
                    status = "disable";
                    wr_mode = <0x1>;
                    wr_status_cmd = <0x1 0x31>;
                };
                spi-norflash@30 {
                    compatible = "st,m25p128";
                    norflash-b-bp0 = <0x2>;
                    norflash-b-bp1 = <0x3>;
                    norflash-b-bp2 = <0x4>;
                    norflash-b-wel = <0x1>;
                    norflash-b-wip = <0x0>;
                    norflash-ext-id = <0x0>;
                    norflash-flags = <0x0>;
                    norflash-jedec-id = <0x202018>;
                    norflash-n-sectors = <0x40>;
                    norflash-name = "m25p128";
                    norflash-sector-size = <0x40000>;
                    norflash-wr_flags = <0x1>;
                    rd_status_cmd = <0x5>;
                    reg = <0x1e>;
                    status = "disable";
                    wr_mode = <0x0>;
                    wr_status_cmd = <0x1>;
                };
                spi-norflash@31 {
                    compatible = "st,m45pe10";
                    norflash-b-wel = <0x1>;
                    norflash-b-wip = <0x0>;
                    norflash-ext-id = <0x0>;
                    norflash-flags = <0x0>;
                    norflash-jedec-id = <0x204011>;
                    norflash-n-sectors = <0x2>;
                    norflash-name = "m45pe10";
                    norflash-sector-size = <0x10000>;
                    norflash-wr_flags = <0x1>;
                    rd_status_cmd = <0x5>;
                    reg = <0x1f>;
                    status = "disable";
                    wr_mode = <0x3>;
                };
                spi-norflash@32 {
                    compatible = "st,m45pe80";
                    norflash-b-wel = <0x1>;
                    norflash-b-wip = <0x0>;
                    norflash-ext-id = <0x0>;
                    norflash-flags = <0x0>;
                    norflash-jedec-id = <0x204014>;
                    norflash-n-sectors = <0x10>;
                    norflash-name = "m45pe80";
                    norflash-sector-size = <0x10000>;
                    norflash-wr_flags = <0x1>;
                    rd_status_cmd = <0x5>;
                    reg = <0x20>;
                    status = "disable";
                    wr_mode = <0x3>;
                };
                spi-norflash@33 {
                    compatible = "st,m45pe16";
                    norflash-b-wel = <0x1>;
                    norflash-b-wip = <0x0>;
                    norflash-ext-id = <0x0>;
                    norflash-flags = <0x0>;
                    norflash-jedec-id = <0x204015>;
                    norflash-n-sectors = <0x20>;
                    norflash-name = "m45pe16";
                    norflash-sector-size = <0x10000>;
                    norflash-wr_flags = <0x1>;
                    rd_status_cmd = <0x5>;
                    reg = <0x21>;
                    status = "disable";
                    wr_mode = <0x3>;
                };
                spi-norflash@34 {
                    compatible = "st,m25pe80";
                    norflash-b-bp0 = <0x2>;
                    norflash-b-bp1 = <0x3>;
                    norflash-b-bp2 = <0x4>;
                    norflash-b-srp0 = <0x7>;
                    norflash-b-wel = <0x1>;
                    norflash-b-wip = <0x0>;
                    norflash-ext-id = <0x0>;
                    norflash-flags = <0x0>;
                    norflash-jedec-id = <0x208014>;
                    norflash-n-sectors = <0x10>;
                    norflash-name = "m25pe80";
                    norflash-sector-size = <0x10000>;
                    norflash-wr_flags = <0x1>;
                    rd_status_cmd = <0x5>;
                    reg = <0x22>;
                    status = "disable";
                    wr_mode = <0x0>;
                    wr_status_cmd = <0x1>;
                };
                spi-norflash@35 {
                    compatible = "st,m25pe16";
                    norflash-b-bp0 = <0x2>;
                    norflash-b-bp1 = <0x3>;
                    norflash-b-bp2 = <0x4>;
                    norflash-b-wel = <0x1>;
                    norflash-b-wip = <0x0>;
                    norflash-ext-id = <0x0>;
                    norflash-flags = <0x1000>;
                    norflash-jedec-id = <0x208015>;
                    norflash-n-sectors = <0x20>;
                    norflash-name = "m25pe16";
                    norflash-sector-size = <0x10000>;
                    norflash-wr_flags = <0x1>;
                    rd_status_cmd = <0x5>;
                    reg = <0x23>;
                    status = "disable";
                    wr_mode = <0x0>;
                    wr_status_cmd = <0x1>;
                };
                spi-norflash@36 {
                    compatible = "winbond,w25x10";
                    norflash-b-bp0 = <0x2>;
                    norflash-b-bp1 = <0x3>;
                    norflash-b-bp2 = <0x4>;
                    norflash-b-srp0 = <0x7>;
                    norflash-b-wel = <0x1>;
                    norflash-b-wip = <0x0>;
                    norflash-ext-id = <0x0>;
                    norflash-flags = <0x1000>;
                    norflash-jedec-id = <0xef3011>;
                    norflash-n-sectors = <0x2>;
                    norflash-name = "w25x10";
                    norflash-sector-size = <0x10000>;
                    norflash-wr_flags = <0x1>;
                    rd_status_cmd = <0x5>;
                    reg = <0x24>;
                    status = "disable";
                    wr_mode = <0x0>;
                    wr_status_cmd = <0x1>;
                };
                spi-norflash@37 {
                    compatible = "winbond,w25x20";
                    norflash-b-bp0 = <0x2>;
                    norflash-b-bp1 = <0x3>;
                    norflash-b-bp2 = <0x4>;
                    norflash-b-srp0 = <0x7>;
                    norflash-b-wel = <0x1>;
                    norflash-b-wip = <0x0>;
                    norflash-ext-id = <0x0>;
                    norflash-flags = <0x1000>;
                    norflash-jedec-id = <0xef3012>;
                    norflash-n-sectors = <0x4>;
                    norflash-name = "w25x20";
                    norflash-sector-size = <0x10000>;
                    norflash-wr_flags = <0x1>;
                    rd_status_cmd = <0x5>;
                    reg = <0x25>;
                    status = "disable";
                    wr_mode = <0x0>;
                    wr_status_cmd = <0x1>;
                };
                spi-norflash@38 {
                    compatible = "winbond,w25x40";
                    norflash-b-bp0 = <0x2>;
                    norflash-b-bp1 = <0x3>;
                    norflash-b-bp2 = <0x4>;
                    norflash-b-srp0 = <0x7>;
                    norflash-b-wel = <0x1>;
                    norflash-b-wip = <0x0>;
                    norflash-ext-id = <0x0>;
                    norflash-flags = <0x1000>;
                    norflash-jedec-id = <0xef3013>;
                    norflash-n-sectors = <0x8>;
                    norflash-name = "w25x40";
                    norflash-sector-size = <0x10000>;
                    norflash-wr_flags = <0x1>;
                    rd_status_cmd = <0x5>;
                    reg = <0x26>;
                    status = "disable";
                    wr_mode = <0x0>;
                    wr_status_cmd = <0x1>;
                };
                spi-norflash@39 {
                    compatible = "winbond,w25x80";
                    norflash-b-bp0 = <0x2>;
                    norflash-b-bp1 = <0x3>;
                    norflash-b-bp2 = <0x4>;
                    norflash-b-srp0 = <0x7>;
                    norflash-b-wel = <0x1>;
                    norflash-b-wip = <0x0>;
                    norflash-ext-id = <0x0>;
                    norflash-flags = <0x1000>;
                    norflash-jedec-id = <0xef3014>;
                    norflash-n-sectors = <0x10>;
                    norflash-name = "w25x80";
                    norflash-sector-size = <0x10000>;
                    norflash-wr_flags = <0x1>;
                    rd_status_cmd = <0x5>;
                    reg = <0x27>;
                    status = "disable";
                    wr_mode = <0x0>;
                    wr_status_cmd = <0x1>;
                };
                spi-norflash@4 {
                    compatible = "atmel,at26f004";
                    norflash-b-wel = <0x1>;
                    norflash-b-wip = <0x0>;
                    norflash-ext-id = <0x0>;
                    norflash-flags = <0x1000>;
                    norflash-jedec-id = <0x1f0400>;
                    norflash-n-sectors = <0x8>;
                    norflash-name = "at26f004";
                    norflash-sector-size = <0x10000>;
                    norflash-wr_flags = <0x1>;
                    rd_status_cmd = <0x5>;
                    reg = <0x4>;
                    status = "disable";
                    wr_mode = <0x0>;
                    wr_status_cmd = <0x1>;
                };
                spi-norflash@40 {
                    compatible = "winbond,w25x16";
                    norflash-b-bp0 = <0x2>;
                    norflash-b-bp1 = <0x3>;
                    norflash-b-bp2 = <0x4>;
                    norflash-b-srp0 = <0x7>;
                    norflash-b-wel = <0x1>;
                    norflash-b-wip = <0x0>;
                    norflash-ext-id = <0x0>;
                    norflash-flags = <0x1000>;
                    norflash-jedec-id = <0xef3015>;
                    norflash-n-sectors = <0x20>;
                    norflash-name = "w25x16";
                    norflash-sector-size = <0x10000>;
                    norflash-wr_flags = <0x1>;
                    rd_status_cmd = <0x5>;
                    reg = <0x28>;
                    status = "disable";
                    wr_mode = <0x0>;
                    wr_status_cmd = <0x1>;
                };
                spi-norflash@41 {
                    compatible = "winbond,w25x32";
                    norflash-b-bp0 = <0x2>;
                    norflash-b-bp1 = <0x3>;
                    norflash-b-bp2 = <0x4>;
                    norflash-b-srp0 = <0x7>;
                    norflash-b-wel = <0x1>;
                    norflash-b-wip = <0x0>;
                    norflash-ext-id = <0x0>;
                    norflash-flags = <0x1000>;
                    norflash-jedec-id = <0xef3016>;
                    norflash-n-sectors = <0x40>;
                    norflash-name = "w25x32";
                    norflash-sector-size = <0x10000>;
                    norflash-wr_flags = <0x1>;
                    rd_status_cmd = <0x5>;
                    reg = <0x29>;
                    status = "disable";
                    wr_mode = <0x0>;
                    wr_status_cmd = <0x1>;
                };
                spi-norflash@42 {
                    compatible = "winbond,w25x64";
                    norflash-b-bp0 = <0x2>;
                    norflash-b-bp1 = <0x3>;
                    norflash-b-bp2 = <0x4>;
                    norflash-b-srp0 = <0x7>;
                    norflash-b-wel = <0x1>;
                    norflash-b-wip = <0x0>;
                    norflash-ext-id = <0x0>;
                    norflash-flags = <0x1000>;
                    norflash-jedec-id = <0xef3017>;
                    norflash-n-sectors = <0x80>;
                    norflash-name = "w25x64";
                    norflash-sector-size = <0x10000>;
                    norflash-wr_flags = <0x1>;
                    rd_status_cmd = <0x5>;
                    reg = <0x2a>;
                    status = "disable";
                    wr_mode = <0x0>;
                    wr_status_cmd = <0x1>;
                };
                spi-norflash@43 {
                    compatible = "winbond,w25q32";
                    norflash-b-bp0 = <0x2>;
                    norflash-b-bp1 = <0x3>;
                    norflash-b-bp2 = <0x4>;
                    norflash-b-qe = <0x9>;
                    norflash-b-srp0 = <0x7>;
                    norflash-b-srp1 = <0x8>;
                    norflash-b-wel = <0x1>;
                    norflash-b-wip = <0x0>;
                    norflash-ext-id = <0x0>;
                    norflash-flags = <0x18a8>;
                    norflash-jedec-id = <0xef4016>;
                    norflash-n-sectors = <0x80>;
                    norflash-name = "w25q32";
                    norflash-sector-size = <0x8000>;
                    norflash-wr_flags = <0x1>;
                    rd_status_cmd = <0x5 0x35>;
                    reg = <0x2b>;
                    status = "disable";
                    wr_mode = <0x0>;
                    wr_status_cmd = <0x1>;
                };
                spi-norflash@44 {
                    compatible = "winbond,w25q64";
                    norflash-b-bp0 = <0x2>;
                    norflash-b-bp1 = <0x3>;
                    norflash-b-bp2 = <0x4>;
                    norflash-b-cmp = <0xe>;
                    norflash-b-qe = <0x9>;
                    norflash-b-srp1 = <0x8>;
                    norflash-b-sus = <0xf>;
                    norflash-b-wel = <0x1>;
                    norflash-b-wip = <0x0>;
                    norflash-ext-id = <0x0>;
                    norflash-flags = <0x18a8>;
                    norflash-jedec-id = <0xef4017>;
                    norflash-n-sectors = <0x80>;
                    norflash-name = "w25q64";
                    norflash-sector-size = <0x10000>;
                    norflash-wr_flags = <0x2>;
                    rd_status_cmd = <0x5 0x35 0x15>;
                    reg = <0x2c>;
                    status = "okay";
                    wr_mode = <0x0>;
                    wr_status_cmd = <0x1 0x31 0x11>;
                };
                spi-norflash@45 {
                    compatible = "winbond,w25q128";
                    norflash-b-bp0 = <0x2>;
                    norflash-b-bp1 = <0x3>;
                    norflash-b-bp2 = <0x4>;
                    norflash-b-cmp = <0xe>;
                    norflash-b-qe = <0x9>;
                    norflash-b-srp0 = <0x7>;
                    norflash-b-srp1 = <0x8>;
                    norflash-b-sus = <0xf>;
                    norflash-b-wel = <0x1>;
                    norflash-b-wip = <0x0>;
                    norflash-ext-id = <0x0>;
                    norflash-flags = <0x18a8>;
                    norflash-jedec-id = <0xef4018>;
                    norflash-n-sectors = <0x100>;
                    norflash-name = "w25q128";
                    norflash-sector-size = <0x10000>;
                    norflash-wr_flags = <0x2>;
                    rd_status_cmd = <0x5 0x35 0x15>;
                    reg = <0x2d>;
                    status = "okay";
                    wr_mode = <0x1>;
                    wr_status_cmd = <0x1 0x31 0x11>;
                };
                spi-norflash@46 {
                    #clock-cells = <0x1>;
                    compatible = "gd,gd25q64";
                    norflash-b-bp0 = <0x2>;
                    norflash-b-bp1 = <0x3>;
                    norflash-b-bp2 = <0x4>;
                    norflash-b-bp3 = <0x5>;
                    norflash-b-bp4 = <0x6>;
                    norflash-b-cmp = <0xe>;
                    norflash-b-qe = <0x9>;
                    norflash-b-srp0 = <0x7>;
                    norflash-b-srp1 = <0x8>;
                    norflash-b-sus = <0xf>;
                    norflash-b-wel = <0x1>;
                    norflash-b-wip = <0x0>;
                    norflash-ext-id = <0x0>;
                    norflash-flags = <0x18f8>;
                    norflash-jedec-id = <0xc84017>;
                    norflash-n-sectors = <0x80>;
                    norflash-name = "gd25q64";
                    norflash-sector-size = <0x10000>;
                    norflash-wr_flags = <0x2>;
                    rd_status_cmd = <0x5 0x35 0x15>;
                    reg = <0x2e>;
                    status = "okay";
                    wr_mode = <0x1>;
                    wr_status_cmd = <0x1 0x31>;
                };
                spi-norflash@47 {
                    compatible = "gd,gd25q128";
                    norflash-b-bp0 = <0x2>;
                    norflash-b-bp1 = <0x3>;
                    norflash-b-bp2 = <0x4>;
                    norflash-b-bp3 = <0x5>;
                    norflash-b-bp4 = <0x6>;
                    norflash-b-cmp = <0xe>;
                    norflash-b-qe = <0x9>;
                    norflash-b-srp0 = <0x7>;
                    norflash-b-srp1 = <0x8>;
                    norflash-b-sus = <0xf>;
                    norflash-b-wel = <0x1>;
                    norflash-b-wip = <0x0>;
                    norflash-ext-id = <0x0>;
                    norflash-flags = <0x18f8>;
                    norflash-jedec-id = <0xc84018>;
                    norflash-n-sectors = <0x100>;
                    norflash-name = "gd25q128";
                    norflash-sector-size = <0x10000>;
                    norflash-wr_flags = <0x2>;
                    rd_status_cmd = <0x5 0x35 0x15>;
                    reg = <0x2f>;
                    status = "okay";
                    wr_mode = <0x1>;
                    wr_status_cmd = <0x1 0x31 0x11>;
                };
                spi-norflash@48 {
                    compatible = "xmc,xm25qh64a";
                    norflash-b-bp0 = <0x2>;
                    norflash-b-bp1 = <0x3>;
                    norflash-b-bp2 = <0x4>;
                    norflash-b-bp3 = <0x5>;
                    norflash-b-qe = <0x8>;
                    norflash-b-srp0 = <0x7>;
                    norflash-b-wel = <0x1>;
                    norflash-b-wip = <0x0>;
                    norflash-ext-id = <0x0>;
                    norflash-flags = <0x58f8>;
                    norflash-jedec-id = <0x207017>;
                    norflash-n-sectors = <0x80>;
                    norflash-name = "xm25qh64a";
                    norflash-sector-size = <0x10000>;
                    norflash-wr_flags = <0x1>;
                    rd_status_cmd = <0x5 0x9 0x95>;
                    reg = <0x30>;
                    status = "okay";
                    wr_mode = <0x0>;
                    wr_status_cmd = <0x1 0xc0>;
                };
                spi-norflash@49 {
                    compatible = "xmc,xm25qh128a";
                    norflash-b-bp0 = <0x2>;
                    norflash-b-bp1 = <0x3>;
                    norflash-b-bp2 = <0x4>;
                    norflash-b-bp3 = <0x5>;
                    norflash-b-qe = <0x8>;
                    norflash-b-srp0 = <0x7>;
                    norflash-b-wel = <0x1>;
                    norflash-b-wip = <0x0>;
                    norflash-ext-id = <0x0>;
                    norflash-flags = <0x58f8>;
                    norflash-jedec-id = <0x207018>;
                    norflash-n-sectors = <0x100>;
                    norflash-name = "xm25qh128a";
                    norflash-sector-size = <0x10000>;
                    norflash-wr_flags = <0x1>;
                    rd_status_cmd = <0x5 0x9 0x95>;
                    reg = <0x31>;
                    status = "okay";
                    wr_mode = <0x0>;
                    wr_status_cmd = <0x1>;
                };
                spi-norflash@5 {
                    compatible = "atmel,at26df081a";
                    norflash-b-wel = <0x1>;
                    norflash-b-wip = <0x0>;
                    norflash-ext-id = <0x0>;
                    norflash-flags = <0x1000>;
                    norflash-jedec-id = <0x1f4501>;
                    norflash-n-sectors = <0x10>;
                    norflash-name = "at26df081a";
                    norflash-sector-size = <0x10000>;
                    norflash-wr_flags = <0x2>;
                    rd_status_cmd = <0x5>;
                    reg = <0x5>;
                    status = "disable";
                    wr_mode = <0x1>;
                    wr_status_cmd = <0x1 0x31>;
                };
                spi-norflash@50 {
                    compatible = "pn,pn26f64b";
                    norflash-b-bp0 = <0x2>;
                    norflash-b-bp1 = <0x3>;
                    norflash-b-bp2 = <0x4>;
                    norflash-b-bp3 = <0x5>;
                    norflash-b-srp0 = <0x7>;
                    norflash-b-wel = <0x1>;
                    norflash-b-wip = <0x0>;
                    norflash-ext-id = <0x0>;
                    norflash-flags = <0x58f8>;
                    norflash-jedec-id = <0x1c7017>;
                    norflash-n-sectors = <0x80>;
                    norflash-name = "pn26f64b";
                    norflash-sector-size = <0x10000>;
                    norflash-wr_flags = <0x1>;
                    rd_status_cmd = <0x5 0x9 0x95>;
                    reg = <0x32>;
                    status = "okay";
                    wr_mode = <0x0>;
                    wr_status_cmd = <0x1>;
                };
                spi-norflash@51 {
                    compatible = "by,by25q64a";
                    norflash-b-bp0 = <0x2>;
                    norflash-b-bp1 = <0x3>;
                    norflash-b-bp2 = <0x4>;
                    norflash-b-bp3 = <0x5>;
                    norflash-b-bp4 = <0x6>;
                    norflash-b-cmp = <0xe>;
                    norflash-b-lb = <0xa>;
                    norflash-b-qe = <0x9>;
                    norflash-b-srp0 = <0x7>;
                    norflash-b-srp1 = <0x8>;
                    norflash-b-sus = <0xf>;
                    norflash-b-wel = <0x1>;
                    norflash-b-wip = <0x0>;
                    norflash-ext-id = <0x0>;
                    norflash-flags = <0x18f8>;
                    norflash-jedec-id = <0x684017>;
                    norflash-n-sectors = <0x80>;
                    norflash-name = "by25q64a";
                    norflash-sector-size = <0x10000>;
                    norflash-wr_flags = <0x2>;
                    rd_status_cmd = <0x5 0x35 0x15>;
                    reg = <0x33>;
                    status = "okay";
                    wr_mode = <0x1>;
                    wr_status_cmd = <0x1 0x31 0x11>;
                };
                spi-norflash@52 {
                    compatible = "by,by25q128a";
                    norflash-b-bp0 = <0x2>;
                    norflash-b-bp1 = <0x3>;
                    norflash-b-bp2 = <0x4>;
                    norflash-b-bp3 = <0x5>;
                    norflash-b-bp4 = <0x6>;
                    norflash-b-cmp = <0xe>;
                    norflash-b-lb = <0xa>;
                    norflash-b-qe = <0x9>;
                    norflash-b-srp0 = <0x7>;
                    norflash-b-srp1 = <0x8>;
                    norflash-b-sus = <0xf>;
                    norflash-b-wel = <0x1>;
                    norflash-b-wip = <0x0>;
                    norflash-ext-id = <0x0>;
                    norflash-flags = <0x18f8>;
                    norflash-jedec-id = <0x684018>;
                    norflash-n-sectors = <0x100>;
                    norflash-name = "by25q128a";
                    norflash-sector-size = <0x10000>;
                    norflash-wr_flags = <0x2>;
                    rd_status_cmd = <0x5 0x35 0x15>;
                    reg = <0x34>;
                    status = "okay";
                    wr_mode = <0x1>;
                    wr_status_cmd = <0x1 0x31 0x11>;
                };
                spi-norflash@53 {
                    compatible = "fm,fm25q64";
                    norflash-b-bp0 = <0x2>;
                    norflash-b-bp1 = <0x3>;
                    norflash-b-bp2 = <0x4>;
                    norflash-b-cmp = <0xe>;
                    norflash-b-lb = <0xa>;
                    norflash-b-qe = <0x9>;
                    norflash-b-srp0 = <0x7>;
                    norflash-b-srp1 = <0x8>;
                    norflash-b-sus = <0xf>;
                    norflash-b-wel = <0x1>;
                    norflash-b-wip = <0x0>;
                    norflash-ext-id = <0x0>;
                    norflash-flags = <0x18f8>;
                    norflash-jedec-id = <0xa14017>;
                    norflash-n-sectors = <0x80>;
                    norflash-name = "fm25q64";
                    norflash-sector-size = <0x10000>;
                    norflash-wr_flags = <0x2>;
                    rd_status_cmd = <0x5 0x35 0x15>;
                    reg = <0x35>;
                    status = "okay";
                    wr_mode = <0x1>;
                    wr_status_cmd = <0x1 0x31 0x11>;
                };
                spi-norflash@54 {
                    compatible = "fm,fm25q128";
                    norflash-b-bp0 = <0x2>;
                    norflash-b-bp1 = <0x3>;
                    norflash-b-bp2 = <0x4>;
                    norflash-b-cmp = <0x6>;
                    norflash-b-qe = <0x9>;
                    norflash-b-srp0 = <0x7>;
                    norflash-b-wel = <0x1>;
                    norflash-b-wip = <0x0>;
                    norflash-ext-id = <0x0>;
                    norflash-flags = <0x18f8>;
                    norflash-jedec-id = <0xa14018>;
                    norflash-n-sectors = <0x100>;
                    norflash-name = "fm25q128";
                    norflash-sector-size = <0x10000>;
                    norflash-wr_flags = <0x2>;
                    rd_status_cmd = <0x5 0x35 0x15>;
                    reg = <0x36>;
                    status = "okay";
                    wr_mode = <0x1>;
                    wr_status_cmd = <0x1 0x31 0x11>;
                };
                spi-norflash@55 {
                    compatible = "zb,zb25vq32";
                    norflash-b-bp0 = <0x2>;
                    norflash-b-bp1 = <0x3>;
                    norflash-b-bp2 = <0x4>;
                    norflash-b-cmp = <0xe>;
                    norflash-b-lb = <0xa>;
                    norflash-b-qe = <0x9>;
                    norflash-b-srp0 = <0x7>;
                    norflash-b-srp1 = <0x8>;
                    norflash-b-sus = <0xf>;
                    norflash-b-wel = <0x1>;
                    norflash-b-wip = <0x0>;
                    norflash-ext-id = <0x0>;
                    norflash-flags = <0x18f8>;
                    norflash-jedec-id = <0x5e4016>;
                    norflash-n-sectors = <0x80>;
                    norflash-name = "zb25vq32";
                    norflash-sector-size = <0x8000>;
                    norflash-wr_flags = <0x2>;
                    rd_status_cmd = <0x5 0x35 0x15>;
                    reg = <0x37>;
                    status = "disable";
                    wr_mode = <0x1>;
                    wr_status_cmd = <0x1 0x31 0x11>;
                };
                spi-norflash@56 {
                    compatible = "zd,zd25q64a";
                    norflash-b-bp0 = <0x2>;
                    norflash-b-bp1 = <0x3>;
                    norflash-b-bp2 = <0x4>;
                    norflash-b-bp3 = <0x6>;
                    norflash-b-srp0 = <0x7>;
                    norflash-b-wel = <0x1>;
                    norflash-b-wip = <0x0>;
                    norflash-ext-id = <0x0>;
                    norflash-flags = <0x18f8>;
                    norflash-jedec-id = <0xba4017>;
                    norflash-n-sectors = <0x80>;
                    norflash-name = "zd25q64a";
                    norflash-sector-size = <0x10000>;
                    norflash-wr_flags = <0x1>;
                    rd_status_cmd = <0x5>;
                    reg = <0x38>;
                    status = "disable";
                    wr_mode = <0x0>;
                    wr_status_cmd = <0x1>;
                };
                spi-norflash@57 {
                    compatible = "zb,zb25vq64";
                    norflash-b-bp0 = <0x2>;
                    norflash-b-bp1 = <0x3>;
                    norflash-b-bp2 = <0x4>;
                    norflash-b-cmp = <0xe>;
                    norflash-b-lb = <0xa>;
                    norflash-b-qe = <0x9>;
                    norflash-b-srp0 = <0x7>;
                    norflash-b-srp1 = <0x8>;
                    norflash-b-sus = <0xf>;
                    norflash-b-wel = <0x1>;
                    norflash-b-wip = <0x0>;
                    norflash-ext-id = <0x0>;
                    norflash-flags = <0x18f8>;
                    norflash-jedec-id = <0x5e4017>;
                    norflash-n-sectors = <0x80>;
                    norflash-name = "zb25vq64";
                    norflash-sector-size = <0x10000>;
                    norflash-wr_flags = <0x2>;
                    rd_status_cmd = <0x5 0x35 0x15>;
                    reg = <0x39>;
                    status = "okay";
                    wr_mode = <0x1>;
                    wr_status_cmd = <0x1 0x31 0x11>;
                };
                spi-norflash@58 {
                    compatible = "zb,zb25vq128";
                    norflash-b-bp0 = <0x2>;
                    norflash-b-bp1 = <0x3>;
                    norflash-b-bp2 = <0x4>;
                    norflash-b-cmp = <0xe>;
                    norflash-b-lb = <0xa>;
                    norflash-b-qe = <0x9>;
                    norflash-b-srp0 = <0x7>;
                    norflash-b-srp1 = <0x8>;
                    norflash-b-sus = <0xf>;
                    norflash-b-wel = <0x1>;
                    norflash-b-wip = <0x0>;
                    norflash-ext-id = <0x0>;
                    norflash-flags = <0x18f8>;
                    norflash-jedec-id = <0x5e4018>;
                    norflash-n-sectors = <0x100>;
                    norflash-name = "zb25vq128";
                    norflash-sector-size = <0x10000>;
                    norflash-wr_flags = <0x2>;
                    rd_status_cmd = <0x5 0x35 0x15>;
                    reg = <0x3a>;
                    status = "okay";
                    wr_mode = <0x1>;
                    wr_status_cmd = <0x1 0x31 0x11>;
                };
                spi-norflash@59 {
                    compatible = "kh,kh25l64";
                    norflash-b-bp0 = <0x2>;
                    norflash-b-bp1 = <0x3>;
                    norflash-b-bp2 = <0x4>;
                    norflash-b-bp3 = <0x5>;
                    norflash-b-qe = <0x6>;
                    norflash-b-wel = <0x1>;
                    norflash-b-wip = <0x0>;
                    norflash-ext-id = <0x0>;
                    norflash-flags = <0x18f0>;
                    norflash-jedec-id = <0xc22017>;
                    norflash-n-sectors = <0x80>;
                    norflash-name = "kh25l64";
                    norflash-sector-size = <0x10000>;
                    norflash-wr_flags = <0x1>;
                    rd_status_cmd = <0x5>;
                    reg = <0x3b>;
                    status = "okay";
                    wr_mode = <0x0>;
                    wr_status_cmd = <0x1>;
                };
                spi-norflash@6 {
                    compatible = "atmel,at26df161a";
                    norflash-b-wel = <0x1>;
                    norflash-b-wip = <0x0>;
                    norflash-ext-id = <0x0>;
                    norflash-flags = <0x1000>;
                    norflash-jedec-id = <0x1f4601>;
                    norflash-n-sectors = <0x20>;
                    norflash-name = "at26df161a";
                    norflash-sector-size = <0x10000>;
                    norflash-wr_flags = <0x1>;
                    rd_status_cmd = <0x5>;
                    reg = <0x6>;
                    status = "disable";
                    wr_mode = <0x0>;
                    wr_status_cmd = <0x1>;
                };
                spi-norflash@60 {
                    compatible = "kh,kh25l128";
                    norflash-b-bp0 = <0x2>;
                    norflash-b-bp1 = <0x3>;
                    norflash-b-bp2 = <0x4>;
                    norflash-b-bp3 = <0x5>;
                    norflash-b-qe = <0x6>;
                    norflash-b-wel = <0x1>;
                    norflash-b-wip = <0x0>;
                    norflash-ext-id = <0x0>;
                    norflash-flags = <0x18f0>;
                    norflash-jedec-id = <0xc22018>;
                    norflash-n-sectors = <0x100>;
                    norflash-name = "kh25l128";
                    norflash-sector-size = <0x10000>;
                    norflash-wr_flags = <0x1>;
                    rd_status_cmd = <0x5>;
                    reg = <0x3c>;
                    status = "okay";
                    wr_mode = <0x0>;
                    wr_status_cmd = <0x1>;
                };
                spi-norflash@61 {
                    compatible = "xt,xt25f64b";
                    norflash-b-bp0 = <0x2>;
                    norflash-b-bp1 = <0x3>;
                    norflash-b-bp2 = <0x4>;
                    norflash-b-cmp = <0xe>;
                    norflash-b-lb = <0xa>;
                    norflash-b-qe = <0x9>;
                    norflash-b-srp0 = <0x7>;
                    norflash-b-srp1 = <0x8>;
                    norflash-b-wel = <0x1>;
                    norflash-b-wip = <0x0>;
                    norflash-ext-id = <0x0>;
                    norflash-flags = <0x18f8>;
                    norflash-jedec-id = <0xb4017>;
                    norflash-n-sectors = <0x80>;
                    norflash-name = "xt25f64b";
                    norflash-sector-size = <0x10000>;
                    norflash-wr_flags = <0x1>;
                    rd_status_cmd = <0x5 0x35>;
                    reg = <0x3d>;
                    status = "okay";
                    wr_mode = <0x0>;
                    wr_status_cmd = <0x1>;
                };
                spi-norflash@62 {
                    compatible = "xt,xt25f128b";
                    norflash-b-bp0 = <0x2>;
                    norflash-b-bp1 = <0x3>;
                    norflash-b-bp2 = <0x4>;
                    norflash-b-cmp = <0xe>;
                    norflash-b-lb = <0xa>;
                    norflash-b-qe = <0x9>;
                    norflash-b-srp0 = <0x7>;
                    norflash-b-srp1 = <0x8>;
                    norflash-b-wel = <0x1>;
                    norflash-b-wip = <0x0>;
                    norflash-ext-id = <0x0>;
                    norflash-flags = <0x18f8>;
                    norflash-jedec-id = <0xb4018>;
                    norflash-n-sectors = <0x100>;
                    norflash-name = "xt25f128b";
                    norflash-sector-size = <0x10000>;
                    norflash-wr_flags = <0x1>;
                    rd_status_cmd = <0x5 0x35>;
                    reg = <0x3e>;
                    status = "okay";
                    wr_mode = <0x0>;
                    wr_status_cmd = <0x1>;
                };
                spi-norflash@63 {
                    compatible = "xmc,xm25qh64b";
                    norflash-b-bp0 = <0x2>;
                    norflash-b-bp1 = <0x3>;
                    norflash-b-bp2 = <0x4>;
                    norflash-b-bp3 = <0x5>;
                    norflash-b-qe = <0x8>;
                    norflash-b-srp0 = <0x7>;
                    norflash-b-wel = <0x1>;
                    norflash-b-wip = <0x0>;
                    norflash-ext-id = <0x0>;
                    norflash-flags = <0x58f8>;
                    norflash-jedec-id = <0x206017>;
                    norflash-n-sectors = <0x80>;
                    norflash-name = "xm25qh64b";
                    norflash-sector-size = <0x10000>;
                    norflash-wr_flags = <0x1>;
                    rd_status_cmd = <0x5 0x9 0x95>;
                    reg = <0x3f>;
                    status = "disable";
                    wr_mode = <0x0>;
                    wr_status_cmd = <0x1>;
                };
                spi-norflash@64 {
                    compatible = "xmc,xm25qh128b";
                    norflash-b-bp0 = <0x2>;
                    norflash-b-bp1 = <0x3>;
                    norflash-b-bp2 = <0x4>;
                    norflash-b-bp3 = <0x5>;
                    norflash-b-qe = <0x8>;
                    norflash-b-srp0 = <0x7>;
                    norflash-b-wel = <0x1>;
                    norflash-b-wip = <0x0>;
                    norflash-ext-id = <0x0>;
                    norflash-flags = <0x58f8>;
                    norflash-jedec-id = <0x206018>;
                    norflash-n-sectors = <0x100>;
                    norflash-name = "xm25qh128b";
                    norflash-sector-size = <0x10000>;
                    norflash-wr_flags = <0x1>;
                    rd_status_cmd = <0x5 0x9 0x95>;
                    reg = <0x40>;
                    status = "disable";
                    wr_mode = <0x0>;
                    wr_status_cmd = <0x1>;
                };
                spi-norflash@65 {
                    compatible = "xmc,xm25qh64c";
                    norflash-b-bp0 = <0x2>;
                    norflash-b-bp1 = <0x3>;
                    norflash-b-bp2 = <0x4>;
                    norflash-b-cmp = <0xe>;
                    norflash-b-qe = <0x9>;
                    norflash-b-srp0 = <0x7>;
                    norflash-b-srp1 = <0x8>;
                    norflash-b-wel = <0x1>;
                    norflash-b-wip = <0x0>;
                    norflash-ext-id = <0x0>;
                    norflash-flags = <0x18f8>;
                    norflash-jedec-id = <0x204017>;
                    norflash-n-sectors = <0x100>;
                    norflash-name = "xm25qh64c";
                    norflash-sector-size = <0x10000>;
                    norflash-wr_flags = <0x1>;
                    rd_status_cmd = <0x5 0x35 0x15>;
                    reg = <0x41>;
                    status = "okay";
                    wr_mode = <0x0>;
                    wr_status_cmd = <0x1 0x31 0x11>;
                };
                spi-norflash@66 {
                    compatible = "xmc,xm25qh128c";
                    norflash-b-bp0 = <0x2>;
                    norflash-b-bp1 = <0x3>;
                    norflash-b-bp2 = <0x4>;
                    norflash-b-cmp = <0xe>;
                    norflash-b-qe = <0x9>;
                    norflash-b-srp0 = <0x7>;
                    norflash-b-srp1 = <0x8>;
                    norflash-b-wel = <0x1>;
                    norflash-b-wip = <0x0>;
                    norflash-ext-id = <0x0>;
                    norflash-flags = <0x18f8>;
                    norflash-jedec-id = <0x204018>;
                    norflash-n-sectors = <0x100>;
                    norflash-name = "xm25qh128c";
                    norflash-sector-size = <0x10000>;
                    norflash-wr_flags = <0x1>;
                    rd_status_cmd = <0x5 0x35 0x15>;
                    reg = <0x42>;
                    status = "okay";
                    wr_mode = <0x0>;
                    wr_status_cmd = <0x1 0x31 0x11>;
                };
                spi-norflash@67 {
                    compatible = "gd,gd25q256";
                    norflash-b-bp0 = <0x2>;
                    norflash-b-bp1 = <0x3>;
                    norflash-b-bp2 = <0x4>;
                    norflash-b-bp3 = <0x5>;
                    norflash-b-bp4 = <0x6>;
                    norflash-b-cmp = <0xe>;
                    norflash-b-qe = <0x9>;
                    norflash-b-srp0 = <0x7>;
                    norflash-b-srp1 = <0x8>;
                    norflash-b-wel = <0x1>;
                    norflash-b-wip = <0x0>;
                    norflash-ext-id = <0x0>;
                    norflash-flags = <0x11888>;
                    norflash-jedec-id = <0xc84019>;
                    norflash-n-sectors = <0x200>;
                    norflash-name = "gd25q256";
                    norflash-sector-size = <0x10000>;
                    norflash-wr_flags = <0x2>;
                    rd_status_cmd = <0x5 0x35 0x15>;
                    reg = <0x43>;
                    status = "disable";
                    wr_mode = <0x1>;
                    wr_status_cmd = <0x1 0x31>;
                };
                spi-norflash@7 {
                    compatible = "atmel,at26df321";
                    norflash-b-wel = <0x1>;
                    norflash-b-wip = <0x0>;
                    norflash-ext-id = <0x0>;
                    norflash-flags = <0x1000>;
                    norflash-jedec-id = <0x1f4701>;
                    norflash-n-sectors = <0x40>;
                    norflash-name = "at26df321";
                    norflash-sector-size = <0x10000>;
                    norflash-wr_flags = <0x1>;
                    rd_status_cmd = <0x5>;
                    reg = <0x7>;
                    status = "disable";
                    wr_mode = <0x0>;
                    wr_status_cmd = <0x1>;
                };
                spi-norflash@8 {
                    compatible = "macronix,mx25l3205d";
                    norflash-b-bp0 = <0x2>;
                    norflash-b-bp1 = <0x3>;
                    norflash-b-bp2 = <0x4>;
                    norflash-b-bp3 = <0x5>;
                    norflash-b-cmp = <0x6>;
                    norflash-b-wel = <0x1>;
                    norflash-b-wip = <0x0>;
                    norflash-ext-id = <0x0>;
                    norflash-flags = <0x1020>;
                    norflash-jedec-id = <0xc22016>;
                    norflash-n-sectors = <0x40>;
                    norflash-name = "mx25l3205d";
                    norflash-sector-size = <0x10000>;
                    norflash-wr_flags = <0x1>;
                    rd_status_cmd = <0x5>;
                    reg = <0x8>;
                    status = "disable";
                    wr_mode = <0x0>;
                    wr_status_cmd = <0x1>;
                };
                spi-norflash@9 {
                    compatible = "macronix,mx25l6405d";
                    norflash-b-bp0 = <0x2>;
                    norflash-b-bp1 = <0x3>;
                    norflash-b-bp2 = <0x4>;
                    norflash-b-bp3 = <0x5>;
                    norflash-b-cmp = <0x6>;
                    norflash-b-wel = <0x1>;
                    norflash-b-wip = <0x0>;
                    norflash-ext-id = <0x0>;
                    norflash-flags = <0x1020>;
                    norflash-jedec-id = <0xc22017>;
                    norflash-n-sectors = <0x80>;
                    norflash-name = "mx25l6405d";
                    norflash-sector-size = <0x10000>;
                    norflash-wr_flags = <0x1>;
                    rd_status_cmd = <0x5>;
                    reg = <0x9>;
                    status = "disable";
                    wr_mode = <0x0>;
                    wr_status_cmd = <0x1>;
                };
            };
            spi-flash@1 {
                compatible = "anyka,ak-spinand";
                reg = <0x1>;
                spi-max-frequency = <0x1c9c380>;
                status = "disable";
            };
        };
        spi1@20128000 {
            #address-cells = <0x1>;
            #size-cells = <0x0>;
            clocks = <0x5 0x5>;
            compatible = "anyka,ak39ev330-spi1";
            interrupts = <0x9 0x0>;
            reg = <0x20128000 0x7fff>;
            status = "disable";
        };
        uart0@20130000 {
            clocks = <0x5 0x6>;
            compatible = "anyka,ak39ev330-uart0";
            current-speed = <0x1c200>;
            fifosize = <0x40>;
            interrupts = <0xa 0x0>;
            pinctrl-0 = <0x10>;
            pinctrl-names = "default";
            reg = <0x20130000 0x7fff>;
            status = "okay";
        };
        uart1@20138000 {
            clocks = <0x5 0x7>;
            compatible = "anyka,ak39ev330-uart1";
            current-speed = <0x1c200>;
            fifosize = <0x40>;
            interrupts = <0xb 0x0>;
            pinctrl-0 = <0x11>;
            pinctrl-names = "default";
            reg = <0x20138000 0x7fff>;
            status = "disable";
        };
        usb@20200000 {
            clocks = <0x5 0xe>;
            compatible = "anyka,ak39ev330-usb";
            interrupts = <0x12 0x0 0x13 0x0>;
            reg = <0x20200000 0xffff>;
            status = "okay";
        };
        vi0@20000000 {
            clock-frequency_isp_clk = <0x16e3600>;
            clock-names = "isp_clk", "mipi_csi_clk", "csi_sclk";
            clocks = <0x5 0x11 0x5 0xf 0x14 0x0>;
            compatible = "anyka,ak39ev330-vi";
            interface = <0x0>;
            interrupts = <0x1 0x0>;
            pinctrl-0 = <0x16>;
            pinctrl-1 = <0x2>;
            pinctrl-2 = <0x17>;
            pinctrl-3 = <0x4>;
            pinctrl-4 = <0x3>;
            pinctrl-5 = <0x18>;
            pinctrl-6 = <0x19>;
            pinctrl-names = "dvp0_12bits", "dvp0_10bits", "dvp0_8bits", "mipi0_2lane", "mipi0_1lane", "csi0_sclk", "csi1_sclk";
            reg = <0x20000000 0x1fff 0x20400000 0xfff>;
            status = "disabled";
            port@0 {
                #address-cells = <0x1>;
                #size-cells = <0x0>;
                endpoint@0 {
                    reg = <0x0>;
                    remote-endpoint = <0x7>;
                };
            };
        };
        video-encoder-m2m@20020000 {
            clocks = <0x5 0x12>;
            compatible = "anyka,ak3918ev200-venc";
            interrupts = <0x2 0x0>;
            reg = <0x20020000 0x1000>;
            status = "disable";
        };
        video-encoder@20020000 {
            clocks = <0x5 0x12>;
            compatible = "anyka,ak39ev330-uio-vencoder";
            interrupts = <0x2 0x0>;
            reg = <0x20020000 0x10000>;
            status = "okay";
        };
    };
    system-control-ic {
        compatible = "anyka,ak39ev330-system-ic";
        interrupt-controller;
        interrupts = <0x3 0x0>;
    };
    timer {
        clock-frequency = <0xb71b00>;
        compatible = "anyka,ak39ev330-system-timer";
        interrupts = <0x6 0x1 0x5 0x1 0x4 0x1 0x3 0x1 0x2 0x1>;
        status = "okay";
    };
    watchdog {
        compatible = "anyka,ak39ev330-wdt";
        def_heartbeat = <0xa>;
        status = "okay";
    };
};
